# LPC176x5x register map
File version: 0.2
CPU: CM3 r0p0, little endian, no MPU, no FPU, 0x5 interrupt priority bits, 0x0 interrupts
Registers are 32-bit, read-write, no defined reset value unless marked. A register's access mark holds for its fields unless they carry their own. Offsets are from the block's base; [hi:lo] are bit positions; {n}, {i} and the like mark numbered series; 'fields as' and 'values as' point back to an identical list.

## PWM1 — Pulse Width Modulators (PWM1)
Base 0x40018000
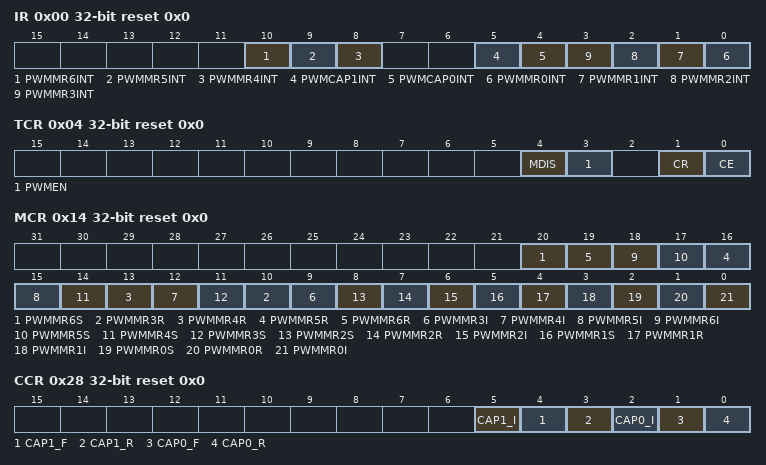
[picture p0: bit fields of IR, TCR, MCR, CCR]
0x00 IR reset 0x0 — Interrupt Register. The IR can be written to clear interrupts, or read to identify which PWM interrupt sources are pending.
  [10] PWMMR6INT — Interrupt flag for PWM match channel 6.
  [9] PWMMR5INT — Interrupt flag for PWM match channel 5.
  [8] PWMMR4INT — Interrupt flag for PWM match channel 4.
  [5] PWMCAP1INT — Interrupt flag for capture input 1 (available in PWM1IR only; this bit is reserved in PWM0IR).
  [4] PWMCAP0INT — Interrupt flag for capture input 0
  [n] PWMMR{n}INT (n=0..3) — Interrupt flag for PWM match channel {n}.
0x04 TCR reset 0x0 — Timer Control Register. The TCR is used to control the Timer Counter functions.
  [4] MDIS — Master Disable (PWM0 only). The two PWMs may be synchronized using the Master Disable control bit. The Master disable bit of the Master PWM (PWM0 module) controls a secondary enable input to both PWMs, as shown in Figure 141. This bit has no function in the Slave PWM (PWM1).
    1=MASTER_USE_PWM0_IS_ (Master use. PWM0 is the master, and both PWMs are enabled for counting.); 0=INDIVIDUAL_USE_THE_ (Individual use. The PWMs are used independently, and the individual Counter Enable bits are used to control the PWMs.)
  [3] PWMEN — PWM Enable
    1=PWM_MODE_IS_ENABLED_ (PWM mode is enabled (counter resets to 1). PWM mode causes the shadow registers to operate in connection with the Match registers. A program write to a Match register will not have an effect on the Match result until the corresponding bit in PWMLER has been set, followed by the occurrence of a PWM Match 0 event. Note that the PWM Match register that determines the PWM rate (PWM Match Register 0 - MR0) must be set up prior to the PWM being enabled. Otherwise a Match event will not occur to cause shadow register contents to become effective.); 0=TIMER_MODE_IS_ENABLE (Timer mode is enabled (counter resets to 0).)
  [1] CR — Counter Reset
    1=THE_PWM_TIMER_COUNTE (The PWM Timer Counter and the PWM Prescale Counter are synchronously reset on the next positive edge of PCLK. The counters remain reset until this bit is returned to zero.); 0=CLEAR_RESET_
  [0] CE — Counter Enable
    1=THE_PWM_TIMER_COUNTE (The PWM Timer Counter and PWM Prescale Counter are enabled for counting.); 0=THE_COUNTERS_ARE_DIS (The counters are disabled.)
0x08 TC reset 0x0 — Timer Counter. The 32 bit TC is incremented every PR+1 cycles of PCLK. The TC is controlled through the TCR.
  [31:0] TC — Timer counter value.
0x0C PR reset 0x0 — Prescale Register. Determines how often the PWM counter is incremented.
  [31:0] PM — Prescale counter maximum value.
0x10 PC reset 0x0 — Prescale Counter. Prescaler for the main PWM counter.
  [31:0] PC — Prescale counter value.
0x14 MCR reset 0x0 — Match Control Register. The MCR is used to control whether an interrupt is generated and if the PWM counter is reset when a Match occurs.
  [20] PWMMR6S — Stop PWM6
    0=DISABLED; 1=STOP_ON_PWMMR6_THE_ (Stop on PWMMR6: the PWMTC and PWMPC will be stopped and PWMTCR bit 0 will be set to 0 if PWMMR6 matches the PWMTC.)
  [3n+1] PWMMR{n}R (n=3..6) — Reset PWM{n}
    0=DISABLED_; 1=RESET_ON_PWMMR{n}_THE (Reset on PWMMR{n}: the PWMTC will be reset if PWMMR{n} matches it.)
  [3n] PWMMR{n}I (n=3..6) — Interrupt PWM{n}
    0=DISABLED_; 1=INTERRUPT_ON_PWMMR{n} (Interrupt on PWMMR{n}: an interrupt is generated when PWMMR{n} matches the value in the PWMTC.)
  [17] PWMMR5S — Stop PWM5
    0=DISABLED; 1=STOP_ON_PWMMR5_THE_ (Stop on PWMMR5: the PWMTC and PWMPC will be stopped and PWMTCR bit 0 will be set to 0 if PWMMR5 matches the PWMTC.)
  [14] PWMMR4S — Stop PWM4
    0=DISABLED; 1=STOP_ON_PWMMR4_THE_ (Stop on PWMMR4: the PWMTC and PWMPC will be stopped and PWMTCR bit 0 will be set to 0 if PWMMR4 matches the PWMTC.)
  [11] PWMMR3S — Stop PWM0
    0=DISABLED; 1=STOP_ON_PWMMR3_THE_ (Stop on PWMMR3: the PWMTC and PWMPC will be stopped and PWMTCR bit 0 will be set to 0 if PWMMR0 matches the PWMTC.)
  [8] PWMMR2S — Stop PWM0
    0=DISABLED; 1=STOP_ON_PWMMR2_THE_ (Stop on PWMMR2: the PWMTC and PWMPC will be stopped and PWMTCR bit 0 will be set to 0 if PWMMR0 matches the PWMTC.)
  [7] PWMMR2R — Reset PWM0
    0=DISABLED_; 1=RESET_ON_PWMMR2_THE (Reset on PWMMR2: the PWMTC will be reset if PWMMR2 matches it.)
  [6] PWMMR2I — Interrupt PWM0
    0=DISABLED_; 1=INTERRUPT_ON_PWMMR2 (Interrupt on PWMMR2: an interrupt is generated when PWMMR2 matches the value in the PWMTC.)
  [5] PWMMR1S — Stop PWM1
    0=DISABLED; 1=STOP_ON_PWMMR1_THE_ (Stop on PWMMR1: the PWMTC and PWMPC will be stopped and PWMTCR bit 0 will be set to 0 if PWMMR1 matches the PWMTC.)
  [4] PWMMR1R — Reset PWM1
    0=DISABLED_; 1=RESET_ON_PWMMR1_THE (Reset on PWMMR1: the PWMTC will be reset if PWMMR1 matches it.)
  [3] PWMMR1I — Interrupt PWM1
    0=DISABLED_; 1=INTERRUPT_ON_PWMMR1 (Interrupt on PWMMR1: an interrupt is generated when PWMMR1 matches the value in the PWMTC.)
  [2] PWMMR0S — Stop PWM0
    0=DISABLED; 1=STOP_ON_PWMMR0_THE_ (Stop on PWMMR0: the PWMTC and PWMPC will be stopped and PWMTCR bit 0 will be set to 0 if PWMMR0 matches the PWMTC.)
  [1] PWMMR0R — Reset PWM0
    0=DISABLED_; 1=RESET_ON_PWMMR0_THE (Reset on PWMMR0: the PWMTC will be reset if PWMMR0 matches it.)
  [0] PWMMR0I — Interrupt PWM0
    0=DISABLED_; 1=INTERRUPT_ON_PWMMR0 (Interrupt on PWMMR0: an interrupt is generated when PWMMR0 matches the value in the PWMTC.)
{0x18+4i} MR{i} reset 0x0 (i=0..3) — Match Register. Match registers are continuously compared to the PWM counter in order to control PWM output edges.
  [31:0] MATCH — Timer counter match value.
0x28 CCR reset 0x0 — Capture Control Register. The CCR controls which edges of the capture inputs are used to load the Capture Registers and whether or not an interrupt is generated for a capture event.
  [5] CAP1_I — Interrupt on PWMn_CAP1 event. Reserved for PWM0.
    0=DISABLED_THIS_FEATU (Disabled. This feature is disabled.); 1=INTERRUPT_A_CR1_LOA (Interrupt. A CR1 load due to a PWMn_CAP1 event will generate an interrupt.)
  [4] CAP1_F — Capture on PWMn_CAP1 falling edge. Reserved for PWM0.
    0=DISABLED_THIS_FEATU (Disabled. This feature is disabled.); 1=FALLING_EDGE_A_SYNC (Falling edge. A synchronously sampled falling edge on PWMn_CAP1 will cause CR1 to be loaded with the contents of TC.)
  [3] CAP1_R — Capture on PWMn_CAP1 rising edge. Reserved for PWM0.
    0=DISABLED_THIS_FEATU (Disabled. This feature is disabled.); 1=RISING_EDGE_A_SYNCH (Rising edge. A synchronously sampled rising edge on PWMn_CAP1 will cause CR1 to be loaded with the contents of the TC.)
  [2] CAP0_I — Interrupt on PWMn_CAP0 event
    0=DISABLED_THIS_FEATU (Disabled. This feature is disabled.); 1=INTERRUPT_A_CR0_LOA (Interrupt. A CR0 load due to a PWMn_CAP0 event will generate an interrupt.)
  [1] CAP0_F — Capture on PWMn_CAP0 falling edge
    0=DISABLED_THIS_FEATU (Disabled. This feature is disabled.); 1=FALLING_EDGE_A_SYNC (Falling edge. A synchronously sampled falling edge on PWMn_CAP0 will cause CR0 to be loaded with the contents of TC.)
  [0] CAP0_R — Capture on PWMn_CAP0 rising edge
    0=DISABLED_THIS_FEATU (Disabled. This feature is disabled.); 1=RISING_EDGE_A_SYNCH (Rising edge. A synchronously sampled rising edge on PWMn_CAP0 will cause CR0 to be loaded with the contents of the TC.)
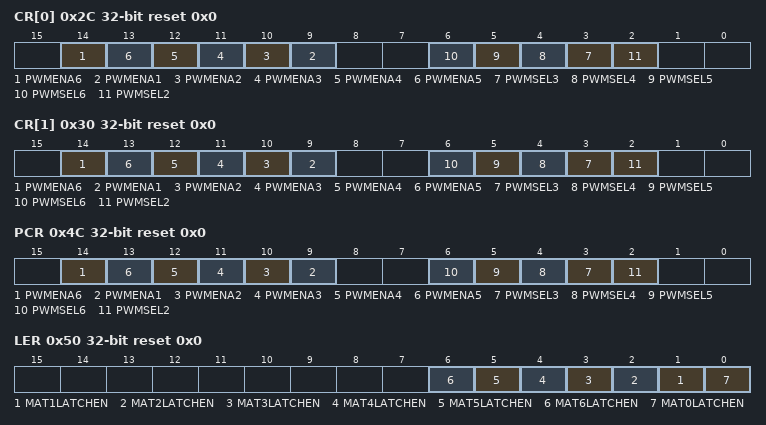
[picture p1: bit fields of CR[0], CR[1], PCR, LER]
0x2C CR[0] reset 0x0 — PWM Control Register. Enables PWM outputs and selects either single edge or double edge controlled PWM outputs.
  [14] PWMENA6 — PWM[6] output enable control. See PWMENA1 for details.
    0=THE_PWM_OUTPUT_IS_DI (The PWM output is disabled.); 1=THE_PWM_OUTPUT_IS_EN (The PWM output is enabled.)
  [n+8] PWMENA{n} (n=1..5) — PWM[{n}] output enable control.
    values as PWMENA6
  [n] PWMSEL{n} (n=3..6) — PWM[{n}] output edge control.
    0=SINGLE_EDGE_CONTROLL (Single edge controlled mode is selected.); 1=DOUBLE_EDGE_CONTROLL (Double edge controlled mode is selected.)
  [2] PWMSEL2 — PWM[2] output single/double edge mode control.
    values as PWMSEL3
0x30 CR[1] reset 0x0 — PWM Control Register. Enables PWM outputs and selects either single edge or double edge controlled PWM outputs.
  fields as CR[0]
{0x30+4i} MR{i} reset 0x0 (i=4..6) — Match Register. Match registers are continuously compared to the PWM counter in order to control PWM output edges.
  [31:0] MATCH — Timer counter match value.
0x4C PCR reset 0x0 — PWM Control Register. Enables PWM outputs and selects either single edge or double edge controlled PWM outputs.
  fields as CR[0]
0x50 LER reset 0x0 — Load Enable Register. Enables use of updated PWM match values.
  [n] MAT{n}LATCHEN (n=1..6) — Enable PWM Match {n} Latch. PWM MR{n} register update control. See bit 0 for details.
  [0] MAT0LATCHEN — Enable PWM Match 0 Latch. PWM MR0 register update control. Writing a one to this bit allows the last value written to the PWM Match Register 0 to be become effective when the timer is next reset by a PWM Match event. See Section 27.6.7.
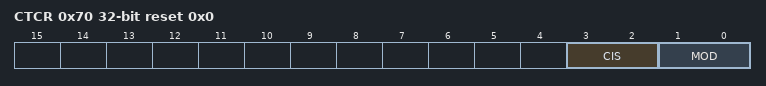
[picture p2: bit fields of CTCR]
0x70 CTCR reset 0x0 — Count Control Register. The CTCR selects between Timer and Counter mode, and in Counter mode selects the signal and edge(s) for counting.
  [3:2] CIS — Count Input Select. When bits 1:0 are not 00, these bits select which PWM_CAP pin carries the signal used to increment the TC. Other combinations are reserved.
    0=FOR_PWM0_00_EQ_PWM0_ (For PWM0: 00 = PWM0_CAP0 (Other combinations are reserved) For PWM1: 00 = PWM1_CAP0, 01 = PWM1_CAP1 (Other combinations are reserved))
  [1:0] MOD — Counter/ Timer Mode
    0=TIMER_MODE_THE_TC_I (Timer Mode: the TC is incremented when the Prescale Counter matches the Prescale register.); 1=RISING_EDGE_COUNTER_ (Rising edge counter Mode: the TC is incremented on rising edges of the PWM_CAP input selected by bits 3:2.); 2=FALLING_EDGE_COUNTER (Falling edge counter Mode: the TC is incremented on falling edges of the PWM_CAP input selected by bits 3:2.); 3=DUAL_EDGE_COUNTER_MO (Dual edge counter Mode: the TC is incremented on both edges of the PWM_CAP input selected by bits 3:2.)
